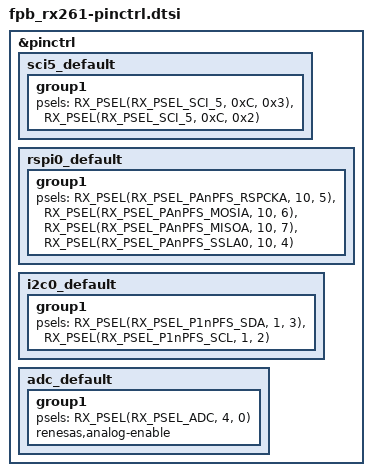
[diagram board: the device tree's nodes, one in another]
/*
 * Copyright (c) 2025 Renesas Electronics Corporation
 *
 * SPDX-License-Identifier: Apache-2.0
 */

&pinctrl {
	sci5_default: sci5_default {
		group1 {
			psels = <RX_PSEL(RX_PSEL_SCI_5, 0xC, 0x3)>, /* TX */
				<RX_PSEL(RX_PSEL_SCI_5, 0xC, 0x2)>; /* RX */
		};
	};

	rspi0_default: rspi0_default {
		group1 {
			psels = <RX_PSEL(RX_PSEL_PAnPFS_RSPCKA, 10, 5)>,
				<RX_PSEL(RX_PSEL_PAnPFS_MOSIA, 10, 6)>,
				<RX_PSEL(RX_PSEL_PAnPFS_MISOA, 10, 7)>,
				<RX_PSEL(RX_PSEL_PAnPFS_SSLA0, 10, 4)>;
		};
	};

	i2c0_default: i2c0_default {
		group1 {
			psels = <RX_PSEL(RX_PSEL_P1nPFS_SDA, 1, 3)>, /* SDA P13*/
				<RX_PSEL(RX_PSEL_P1nPFS_SCL, 1, 2)>; /* SCL P12*/
		};
	};

	adc_default: adc_default {
		group1 {
			/* input */
			psels = <RX_PSEL(RX_PSEL_ADC, 4, 0)>;
			renesas,analog-enable;
		};
	};
};
